# nrf54l15_enga_flpr register map
Vendor: Nordic Semiconductor; Series: nrf54l; File version: 1
Registers are 32-bit, read-write, reset 0x0 unless marked. A register's access mark holds for its fields unless they carry their own. Offsets are from the block's base; [hi:lo] are bit positions; lines under a group give offsets from that group.

## GLOBAL_RESET_NS — Reset control 0
Base 0x4010E000; alternate view of GLOBAL_CLOCK_NS
Same registers: GLOBAL_RESET_S 0x5010E000 (alternate view of GLOBAL_CLOCK_S)
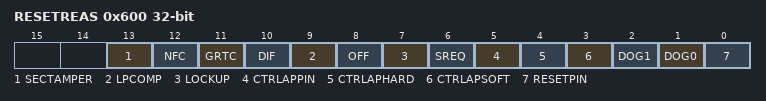
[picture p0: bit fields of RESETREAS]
0x600 RESETREAS — Reset reason
  [all] fields
    0=NotDetected; 1=Detected
  [13] SECTAMPER — Reset due to illegal tampering of the device
  [12] NFC — Reset after wakeup from System OFF mode due to NFC field being detected
  [11] GRTC — Reset due to wakeup from GRTC
  [10] DIF — Reset triggered by Debug Interface
  [9] LPCOMP — Reset due to wakeup from System OFF mode when wakeup is triggered by ANADETECT signal from LPCOMP
  [8] OFF — Reset due to wakeup from System OFF mode when wakeup is triggered by DETECT signal from GPIO
  [7] LOCKUP — Reset from CPU lockup detected
  [6] SREQ — Reset from soft reset detected
  [5] CTRLAPPIN — Reset due to CTRL-AP pin reset
  [4] CTRLAPHARD — Reset due to CTRL-AP hard reset
  [3] CTRLAPSOFT — Soft reset from CTRL-AP detected
  [2] DOG1 — Reset from watchdog timer 1 detected
  [1] DOG0 — Reset from watchdog timer 0 detected
  [0] RESETPIN — Reset from pin reset detected

## GLOBAL_OSCILLATORS_NS — Oscillator control 0
Base 0x40120000
Same registers: GLOBAL_OSCILLATORS_S 0x50120000
0x700 XOSC32M group — 32 MHz oscillator control
  0x10 CLOCKQUALITY ro — Clock quality indicator
    [1:0] INDICATOR
      0=NoStatus (XOSC32M status is not defined); 1=Starting (XOSC32M has started but has not yet reached the specified frequency tolerance requirement fTOL_HFXO); 3=Started (XOSC32M has started and is operating with the specified frequency tolerance requirement fTOL_HFXO)
  0x14 CONFIG group — Unspecified
    0x08 INTCAP reset 0x24 — Crystal load capacitor as seen by the crystal across its terminals, including pin capacitance but excluding PCB stray capacitance.
      [5:0] VAL
0x800 PLL group — Oscillator control
  0x00 FREQ reset 0x3 — CPU frequency
    [1:0] FREQ — Select CPU speed
      1=CK128M (128 MHz); 3=CK64M (64 MHz)
  0x04 CURRENTFREQ ro reset 0x3 — Current CPU frequency
    [1:0] CURRENTFREQ — Active CPU speed
      1=CK128M (128 MHz); 3=CK64M (64 MHz)
0x900 XOSC32KI group — 32 kHz oscillator control
  0x04 INTCAP — Programmable capacitance of XL1 and XL2
    [5:0] VAL — Crystal load capacitor as seen by the crystal across its terminals, including pin capacitance but excluding PCB stray capacitance.

## GLOBAL_REGULATORS_NS — Voltage regulators 0
Base 0x40120000; alternate view of GLOBAL_OSCILLATORS_NS
Same registers: GLOBAL_REGULATORS_S 0x50120000 (alternate view of GLOBAL_OSCILLATORS_S)
0x400 VREGM group — Medium Voltage Regulator
  0x00 ENABLE reset 0x1 — Enable register for VREGM
    [0] ENABLE — Enable the regulator
      0=Disabled (Disable the regulator); 1=Enabled (Enable the regulator)
0x500 SYSTEMOFF wo
  [0] SYSTEMOFF — Enable System OFF mode
    1=Enter (Enable System OFF mode)
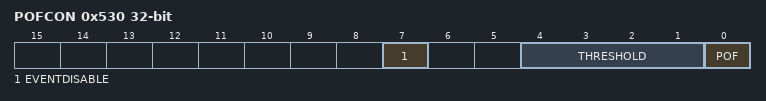
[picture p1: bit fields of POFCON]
0x530 POFCON — Power-fail comparator configuration
  [7] EVENTDISABLE — Disable the POFWARN power-fail warning event
    0=Enabled (POFWARN event is generated); 1=Disabled (POFWARN event is not generated)
  [4:1] THRESHOLD — Power-fail comparator threshold setting
    0=V17 (Set threshold to 1.7 V); 1=V18 (Set threshold to 1.8 V); 2=V19 (Set threshold to 1.9 V); 3=V20 (Set threshold to 2.0 V); 4=V21 (Set threshold to 2.1 V); 5=V22 (Set threshold to 2.2 V); 6=V23 (Set threshold to 2.3 V); 7=V24 (Set threshold to 2.4 V); 8=V25 (Set threshold to 2.5 V); 9=V26 (Set threshold to 2.6 V); 10=V27 (Set threshold to 2.7 V); 11=V28 (Set threshold to 2.8 V)
  [0] POF — Enable or disable power-fail comparator
    0=Disabled; 1=Enabled
0x534 POFSTAT ro — Power-fail comparator status register
  [0] COMPARATOR — Power-fail comparator status
    0=Above (Voltage detected above VPOF threshold); 1=Below (Voltage detected below VPOF threshold)
0x600 VREGMAIN group — Main voltage regulator
  0x00 DCDCEN — Enable DC/DC converter for better power efficiency
    [0] VAL — Enable DC/DC converter
      0=Disable DC/DC converter and use LDO; 1=Enable DC/DC converter
  0x04 INDUCTORDET ro — VREGMAIN inductor detection
    [0] DETECTED
      0=InductorNotDetected (VREGMAIN inductor not detected); 1=InductorDetected (VREGMAIN inductor detected)

## Notices in the file
Copyright (c) 2010 - 2024, Nordic Semiconductor ASA All rights reserved.
SPDX-License-Identifier: BSD-3-Clause
Redistribution and use in source and binary forms, with or without
modification, are permitted provided that the following conditions are met:
1. Redistributions of source code must retain the above copyright notice, this
list of conditions and the following disclaimer.
2. Redistributions in binary form must reproduce the above copyright
notice, this list of conditions and the following disclaimer in the
documentation and/or other materials provided with the distribution.
3. Neither the name of Nordic Semiconductor ASA nor the names of its
contributors may be used to endorse or promote products derived from this
software without specific prior written permission.
THIS SOFTWARE IS PROVIDED BY THE COPYRIGHT HOLDERS AND CONTRIBUTORS "AS IS"
AND ANY EXPRESS OR IMPLIED WARRANTIES, INCLUDING, BUT NOT LIMITED TO, THE
IMPLIED WARRANTIES OF MERCHANTABILITY, AND FITNESS FOR A PARTICULAR PURPOSE
ARE DISCLAIMED. IN NO EVENT SHALL NORDIC SEMICONDUCTOR ASA OR CONTRIBUTORS BE
LIABLE FOR ANY DIRECT, INDIRECT, INCIDENTAL, SPECIAL, EXEMPLARY, OR
CONSEQUENTIAL DAMAGES (INCLUDING, BUT NOT LIMITED TO, PROCUREMENT OF
SUBSTITUTE GOODS OR SERVICES; LOSS OF USE, DATA, OR PROFITS; OR BUSINESS
INTERRUPTION) HOWEVER CAUSED AND ON ANY THEORY OF LIABILITY, WHETHER IN
CONTRACT, STRICT LIABILITY, OR TORT (INCLUDING NEGLIGENCE OR OTHERWISE)
ARISING IN ANY WAY OUT OF THE USE OF THIS SOFTWARE, EVEN IF ADVISED OF THE
POSSIBILITY OF SUCH DAMAGE.
